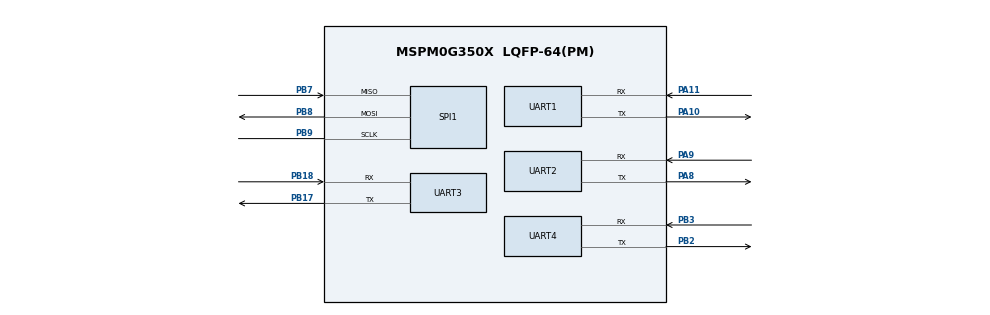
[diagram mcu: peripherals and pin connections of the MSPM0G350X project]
/**
 * @cliArgs --device "MSPM0G350X" --part "Default" --package "LQFP-64(PM)" --product "mspm0_sdk@2.10.00.04"
 * @versions {"tool":"1.27.1+4634"}
 */
scripting.excludeFromBuild("device.opt");
scripting.excludeFromBuild("device.lds.genlibs");
scripting.excludeFromBuild("Event.dot");

/**
 * Import the modules used in this configuration.
 */
const GPIO          = scripting.addModule("/ti/driverlib/GPIO", {}, false);
const GPIO1         = GPIO.addInstance();
const GPIO2         = GPIO.addInstance();
const GPIO3         = GPIO.addInstance();
const SPI           = scripting.addModule("/ti/driverlib/SPI", {}, false);
const SPI1          = SPI.addInstance();
const SYSCTL        = scripting.addModule("/ti/driverlib/SYSCTL");
const SYSTICK       = scripting.addModule("/ti/driverlib/SYSTICK");
const TIMER         = scripting.addModule("/ti/driverlib/TIMER", {}, false);
const TIMER1        = TIMER.addInstance();
const TIMER2        = TIMER.addInstance();
const UART          = scripting.addModule("/ti/driverlib/UART", {}, false);
const UART1         = UART.addInstance();
const UART2         = UART.addInstance();
const UART3         = UART.addInstance();
const UART4         = UART.addInstance();
const ProjectConfig = scripting.addModule("/ti/project_config/ProjectConfig");

/**
 * Write custom configuration values to the imported modules.
 */
const divider9       = system.clockTree["UDIV"];
divider9.divideValue = 2;

const gate7  = system.clockTree["MFCLKGATE"];
gate7.enable = true;

const multiplier2         = system.clockTree["PLL_QDIV"];
multiplier2.multiplyValue = 4;

const mux4       = system.clockTree["EXHFMUX"];
mux4.inputSelect = "EXHFMUX_XTAL";

const mux8       = system.clockTree["HSCLKMUX"];
mux8.inputSelect = "HSCLKMUX_SYSPLL0";

const mux12       = system.clockTree["SYSPLLMUX"];
mux12.inputSelect = "zSYSPLLMUX_HFCLK";

const pinFunction4        = system.clockTree["HFXT"];
pinFunction4.inputFreq    = 40;
pinFunction4.enable       = true;
pinFunction4.HFXTStartup  = 10;
pinFunction4.HFCLKMonitor = true;

GPIO1.$name                              = "GPIO_BOARD";
GPIO1.associatedPins.create(2);
GPIO1.associatedPins[0].$name            = "LED";
GPIO1.associatedPins[0].assignedPort     = "PORTB";
GPIO1.associatedPins[0].assignedPin      = "22";
GPIO1.associatedPins[1].$name            = "KEY";
GPIO1.associatedPins[1].direction        = "INPUT";
GPIO1.associatedPins[1].assignedPort     = "PORTB";
GPIO1.associatedPins[1].assignedPin      = "21";
GPIO1.associatedPins[1].internalResistor = "PULL_UP";
GPIO1.associatedPins[1].interruptEn      = true;
GPIO1.associatedPins[1].polarity         = "FALL";

const Board = scripting.addModule("/ti/driverlib/Board", {}, false);

GPIO2.$name                         = "GPIO_LCD";
GPIO2.port                          = "PORTB";
GPIO2.associatedPins.create(3);
GPIO2.associatedPins[0].$name       = "RES";
GPIO2.associatedPins[0].ioStructure = "SD";
GPIO2.associatedPins[0].assignedPin = "10";
GPIO2.associatedPins[1].$name       = "DC";
GPIO2.associatedPins[1].ioStructure = "SD";
GPIO2.associatedPins[1].assignedPin = "11";
GPIO2.associatedPins[2].$name       = "BLK";
GPIO2.associatedPins[2].ioStructure = "SD";
GPIO2.associatedPins[2].assignedPin = "26";

GPIO3.$name                          = "SPI_CS";
GPIO3.port                           = "PORTB";
GPIO3.associatedPins.create(2);
GPIO3.associatedPins[0].assignedPin  = "6";
GPIO3.associatedPins[0].$name        = "FLASH";
GPIO3.associatedPins[0].ioStructure  = "SD";
GPIO3.associatedPins[0].initialValue = "SET";
GPIO3.associatedPins[1].$name        = "LCD";
GPIO3.associatedPins[1].assignedPin  = "14";
GPIO3.associatedPins[1].ioStructure  = "SD";
GPIO3.associatedPins[1].initialValue = "SET";

SPI1.frameFormat                        = "MOTO3";
SPI1.$name                              = "SPI1";
SPI1.targetBitRate                      = 20000000;
SPI1.enabledDMAEvent1Triggers           = "DL_SPI_DMA_INTERRUPT_RX";
SPI1.enabledDMAEvent2Triggers           = "DL_SPI_DMA_INTERRUPT_TX";
SPI1.sclkPinConfig.direction            = scripting.forceWrite("OUTPUT");
SPI1.sclkPinConfig.onlyInternalResistor = scripting.forceWrite(false);
SPI1.sclkPinConfig.passedPeripheralType = scripting.forceWrite("Digital");
SPI1.sclkPinConfig.$name                = "ti_driverlib_gpio_GPIOPinGeneric2";
SPI1.mosiPinConfig.direction            = scripting.forceWrite("OUTPUT");
SPI1.mosiPinConfig.hideOutputInversion  = scripting.forceWrite(false);
SPI1.mosiPinConfig.onlyInternalResistor = scripting.forceWrite(false);
SPI1.mosiPinConfig.passedPeripheralType = scripting.forceWrite("Digital");
SPI1.mosiPinConfig.$name                = "ti_driverlib_gpio_GPIOPinGeneric3";
SPI1.misoPinConfig.onlyInternalResistor = scripting.forceWrite(false);
SPI1.misoPinConfig.passedPeripheralType = scripting.forceWrite("Digital");
SPI1.misoPinConfig.$name                = "ti_driverlib_gpio_GPIOPinGeneric4";
SPI1.peripheral.$assign                 = "SPI1";
SPI1.peripheral.sclkPin.$assign         = "PB9";
SPI1.peripheral.mosiPin.$assign         = "PB8";
SPI1.peripheral.misoPin.$assign         = "PB7";
SPI1.DMA_CHANNEL_EVENT1.$name           = "DMA_SPI1_RX";
SPI1.DMA_CHANNEL_EVENT1.addressMode     = "f2b";
SPI1.DMA_CHANNEL_EVENT1.srcLength       = "BYTE";
SPI1.DMA_CHANNEL_EVENT1.dstLength       = "BYTE";
SPI1.DMA_CHANNEL_EVENT2.$name           = "DMA_SPI1_TX";
SPI1.DMA_CHANNEL_EVENT2.addressMode     = "b2f";
SPI1.DMA_CHANNEL_EVENT2.srcLength       = "BYTE";
SPI1.DMA_CHANNEL_EVENT2.dstLength       = "BYTE";

SYSCTL.clockTreeEn = true;

SYSTICK.periodEnable      = true;
SYSTICK.interruptEnable   = true;
SYSTICK.interruptPriority = "0";
SYSTICK.systickEnable     = true;
SYSTICK.period            = 80000;

TIMER1.timerPeriod        = "1ms";
TIMER1.interrupts         = ["ZERO"];
TIMER1.$name              = "TIMER_TASK";
TIMER1.timerMode          = "PERIODIC";
TIMER1.peripheral.$assign = "TIMG0";

TIMER2.timerPeriod        = "50us";
TIMER2.interrupts         = ["ZERO"];
TIMER2.$name              = "UART_RX_IDLE";
TIMER2.timerMode          = "ONE_SHOT";
TIMER2.peripheral.$assign = "TIMG8";

UART1.$name                            = "UART_DEBUG";
UART1.targetBaudRate                   = 2000000;
UART1.enabledDMATXTriggers             = "DL_UART_DMA_INTERRUPT_TX";
UART1.enableFIFO                       = true;
UART1.peripheral.$assign               = "UART0";
UART1.peripheral.rxPin.$assign         = "PA11";
UART1.peripheral.txPin.$assign         = "PA10";
UART1.txPinConfig.direction            = scripting.forceWrite("OUTPUT");
UART1.txPinConfig.hideOutputInversion  = scripting.forceWrite(false);
UART1.txPinConfig.onlyInternalResistor = scripting.forceWrite(false);
UART1.txPinConfig.passedPeripheralType = scripting.forceWrite("Digital");
UART1.txPinConfig.$name                = "ti_driverlib_gpio_GPIOPinGeneric0";
UART1.rxPinConfig.hideOutputInversion  = scripting.forceWrite(false);
UART1.rxPinConfig.onlyInternalResistor = scripting.forceWrite(false);
UART1.rxPinConfig.passedPeripheralType = scripting.forceWrite("Digital");
UART1.rxPinConfig.$name                = "ti_driverlib_gpio_GPIOPinGeneric1";
UART1.DMA_CHANNEL_TX.$name             = "DMA_UART0_TX";
UART1.DMA_CHANNEL_TX.srcLength         = "BYTE";
UART1.DMA_CHANNEL_TX.dstLength         = "BYTE";
UART1.DMA_CHANNEL_TX.addressMode       = "b2f";

UART2.$name                            = "UART1";
UART2.peripheral.$assign               = "UART1";
UART2.peripheral.rxPin.$assign         = "PA9";
UART2.peripheral.txPin.$assign         = "PA8";
UART2.txPinConfig.$name                = "ti_driverlib_gpio_GPIOPinGeneric5";
UART2.txPinConfig.direction            = scripting.forceWrite("OUTPUT");
UART2.txPinConfig.hideOutputInversion  = scripting.forceWrite(false);
UART2.txPinConfig.onlyInternalResistor = scripting.forceWrite(false);
UART2.txPinConfig.passedPeripheralType = scripting.forceWrite("Digital");
UART2.rxPinConfig.$name                = "ti_driverlib_gpio_GPIOPinGeneric6";
UART2.rxPinConfig.hideOutputInversion  = scripting.forceWrite(false);
UART2.rxPinConfig.onlyInternalResistor = scripting.forceWrite(false);
UART2.rxPinConfig.passedPeripheralType = scripting.forceWrite("Digital");

UART3.$name                            = "UART2";
UART3.peripheral.$assign               = "UART2";
UART3.peripheral.rxPin.$assign         = "PB18";
UART3.peripheral.txPin.$assign         = "PB17";
UART3.txPinConfig.$name                = "ti_driverlib_gpio_GPIOPinGeneric7";
UART3.txPinConfig.direction            = scripting.forceWrite("OUTPUT");
UART3.txPinConfig.hideOutputInversion  = scripting.forceWrite(false);
UART3.txPinConfig.onlyInternalResistor = scripting.forceWrite(false);
UART3.txPinConfig.passedPeripheralType = scripting.forceWrite("Digital");
UART3.rxPinConfig.$name                = "ti_driverlib_gpio_GPIOPinGeneric8";
UART3.rxPinConfig.hideOutputInversion  = scripting.forceWrite(false);
UART3.rxPinConfig.onlyInternalResistor = scripting.forceWrite(false);
UART3.rxPinConfig.passedPeripheralType = scripting.forceWrite("Digital");

UART4.$name                            = "UART3";
UART4.peripheral.$assign               = "UART3";
UART4.peripheral.rxPin.$assign         = "PB3";
UART4.peripheral.txPin.$assign         = "PB2";
UART4.txPinConfig.$name                = "ti_driverlib_gpio_GPIOPinGeneric9";
UART4.txPinConfig.direction            = scripting.forceWrite("OUTPUT");
UART4.txPinConfig.hideOutputInversion  = scripting.forceWrite(false);
UART4.txPinConfig.onlyInternalResistor = scripting.forceWrite(false);
UART4.txPinConfig.passedPeripheralType = scripting.forceWrite("Digital");
UART4.rxPinConfig.$name                = "ti_driverlib_gpio_GPIOPinGeneric10";
UART4.rxPinConfig.hideOutputInversion  = scripting.forceWrite(false);
UART4.rxPinConfig.onlyInternalResistor = scripting.forceWrite(false);
UART4.rxPinConfig.passedPeripheralType = scripting.forceWrite("Digital");

ProjectConfig.genLibCMSIS        = true;
ProjectConfig.migrationCondition = true;
ProjectConfig.compiler           = "gcc";

/**
 * Pinmux solution for unlocked pins/peripherals. This ensures that minor changes to the automatic solver in a future
 * version of the tool will not impact the pinmux you originally saw.  These lines can be completely deleted in order to
 * re-solve from scratch.
 */
pinFunction4.peripheral.$suggestSolution            = "SYSCTL";
pinFunction4.peripheral.hfxInPin.$suggestSolution   = "PA5";
pinFunction4.peripheral.hfxOutPin.$suggestSolution  = "PA6";
GPIO1.associatedPins[0].pin.$suggestSolution        = "PB22";
GPIO1.associatedPins[1].pin.$suggestSolution        = "PB21";
Board.peripheral.$suggestSolution                   = "DEBUGSS";
Board.peripheral.swclkPin.$suggestSolution          = "PA20";
Board.peripheral.swdioPin.$suggestSolution          = "PA19";
GPIO2.associatedPins[0].pin.$suggestSolution        = "PB10";
GPIO2.associatedPins[1].pin.$suggestSolution        = "PB11";
GPIO2.associatedPins[2].pin.$suggestSolution        = "PB26";
GPIO3.associatedPins[0].pin.$suggestSolution        = "PB6";
GPIO3.associatedPins[1].pin.$suggestSolution        = "PB14";
SPI1.DMA_CHANNEL_EVENT1.peripheral.$suggestSolution = "DMA_CH2";
SPI1.DMA_CHANNEL_EVENT2.peripheral.$suggestSolution = "DMA_CH1";
UART1.DMA_CHANNEL_TX.peripheral.$suggestSolution    = "DMA_CH0";
